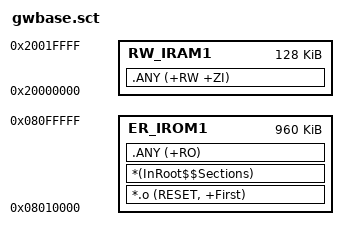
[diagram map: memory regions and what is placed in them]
; *************************************************************
; APP 区散转文件（OTA 方案 A：Bootloader 占前 64KB）
;
; 0x08000000 - 0x08007FFF  16K*2  Bootloader
; 0x08008000 - 0x0800BFFF  16K    启动标志 主份
; 0x0800C000 - 0x0800FFFF  16K    启动标志 备份
; 0x08010000 - 0x080FFFFF  960K   APP（本文件描述的区）
;
; 为什么不用"Target 对话框里的 IROM"：
; 实测这套 Keil 会忽略 .uvprojx 里的 IROM，始终按器件默认 1MB 生成散转，
; 结果固件还在 0x08000000，把 Bootloader 盖掉。写成显式文件最稳。
; *************************************************************

LR_IROM1 0x08010000 0x000F0000  {          ; 加载区：起始 0x08010000，大小 960KB
  ER_IROM1 0x08010000 0x000F0000  {        ; 执行区与加载区同址
   *.o (RESET, +First)                     ; 中断向量表必须放在最前面
   *(InRoot$$Sections)
   .ANY (+RO)
  }
  RW_IRAM1 0x20000000 0x00020000  {        ; 128KB 主 SRAM
   .ANY (+RW +ZI)
  }
}
